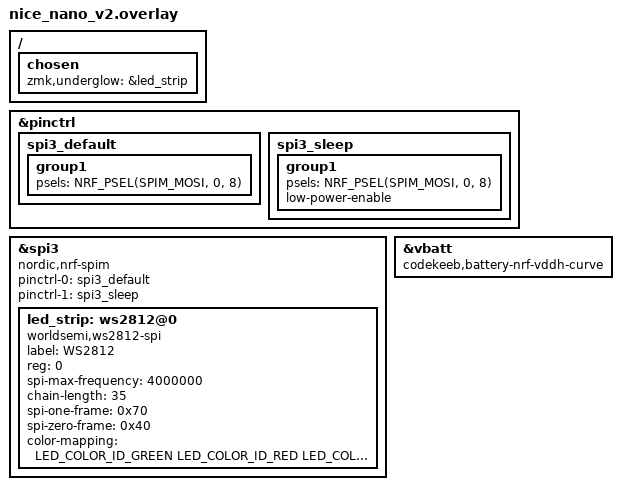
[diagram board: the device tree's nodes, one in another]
#include <dt-bindings/led/led.h>
&pinctrl {
    spi3_default: spi3_default {
        group1 {
            psels = <NRF_PSEL(SPIM_MOSI, 0, 8)>;
        };
    };
    spi3_sleep: spi3_sleep {
        group1 {
            psels = <NRF_PSEL(SPIM_MOSI, 0, 8)>;
            low-power-enable;
        };
    };
};
&spi3 {
  compatible = "nordic,nrf-spim";
  status = "okay";
  pinctrl-0 = <&spi3_default>;
  pinctrl-1 = <&spi3_sleep>;
  pinctrl-names = "default", "sleep";
  led_strip: ws2812@0 {
    compatible = "worldsemi,ws2812-spi";
    label = "WS2812";
    /* SPI */
    reg = <0>; /* ignored, but necessary for SPI bindings */
    spi-max-frequency = <4000000>;
    /* WS2812 */
    chain-length = <35>; /* n�mero de LEDs actualizado a 35 seg�n documentaci�n */
    spi-one-frame = <0x70>;
    spi-zero-frame = <0x40>;
    color-mapping = <LED_COLOR_ID_GREEN
                          LED_COLOR_ID_RED
                          LED_COLOR_ID_BLUE>;
  };
};
/ {
    chosen {
        zmk,underglow = &led_strip;
    };
};

/* Sustituye el driver de bateria del nice!nano (recta 4.20-3.45 V) por el
 * driver propio con curva de descarga LiPo real (src/battery_nrf_vddh_curve.c).
 * El % que muestra la OLED sale del voltaje: los mAh de la bateria no
 * intervienen en el calculo. */
&vbatt {
    compatible = "codekeeb,battery-nrf-vddh-curve";
};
